VERSION ""

NS_ :

BS_:
BU_:
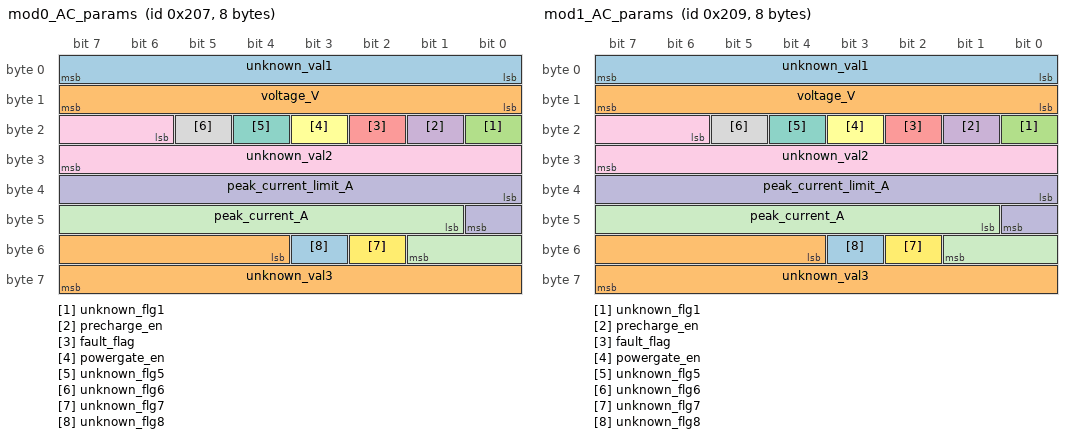
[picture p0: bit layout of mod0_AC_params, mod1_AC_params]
BO_ 519 mod0_AC_params: 8 Vector__XXX
   SG_ unknown_val1 : 0|8@1+ (1,0) [0|1] "" Vector__XXX
   SG_ voltage_V : 8|8@1+ (1,0) [0|1] "" Vector__XXX
   SG_ unknown_flg1 : 16|1@1+ (1,0) [0|1] "" Vector__XXX
   SG_ precharge_en : 17|1@1+ (1,0) [0|1] "" Vector__XXX
   SG_ fault_flag : 18|1@1+ (1,0) [0|1] "" Vector__XXX
   SG_ powergate_en : 19|1@1+ (1,0) [0|1] "" Vector__XXX
   SG_ unknown_flg5 : 20|1@1+ (1,0) [0|1] "" Vector__XXX
   SG_ unknown_flg6 : 21|1@1+ (1,0) [0|1] "" Vector__XXX
   SG_ unknown_val2 : 22|10@1- (1,0) [0|1] "" Vector__XXX
   SG_ peak_current_limit_A : 32|9@1+ (0.1,0) [0|1] "" Vector__XXX
   SG_ peak_current_A : 41|9@1+ (0.1,0) [0|1] "" Vector__XXX
   SG_ unknown_flg7 : 50|1@1+ (1,0) [0|1] "" Vector__XXX
   SG_ unknown_flg8 : 51|1@1+ (1,0) [0|1] "" Vector__XXX
   SG_ unknown_val3 : 52|12@1+ (1,0) [0|1] "" Vector__XXX

BO_ 521 mod1_AC_params: 8 Vector__XXX
   SG_ unknown_val1 : 0|8@1+ (1,0) [0|1] "" Vector__XXX
   SG_ voltage_V : 8|8@1+ (1,0) [0|1] "" Vector__XXX
   SG_ unknown_flg1 : 16|1@1+ (1,0) [0|1] "" Vector__XXX
   SG_ precharge_en : 17|1@1+ (1,0) [0|1] "" Vector__XXX
   SG_ fault_flag : 18|1@1+ (1,0) [0|1] "" Vector__XXX
   SG_ powergate_en : 19|1@1+ (1,0) [0|1] "" Vector__XXX
   SG_ unknown_flg5 : 20|1@1+ (1,0) [0|1] "" Vector__XXX
   SG_ unknown_flg6 : 21|1@1+ (1,0) [0|1] "" Vector__XXX
   SG_ unknown_val2 : 22|10@1- (1,0) [0|1] "" Vector__XXX
   SG_ peak_current_limit_A : 32|9@1+ (0.1,0) [0|1] "" Vector__XXX
   SG_ peak_current_A : 41|9@1+ (0.1,0) [0|1] "" Vector__XXX
   SG_ unknown_flg7 : 50|1@1+ (1,0) [0|1] "" Vector__XXX
   SG_ unknown_flg8 : 51|1@1+ (1,0) [0|1] "" Vector__XXX
   SG_ unknown_val3 : 52|12@1+ (1,0) [0|1] "" Vector__XXX

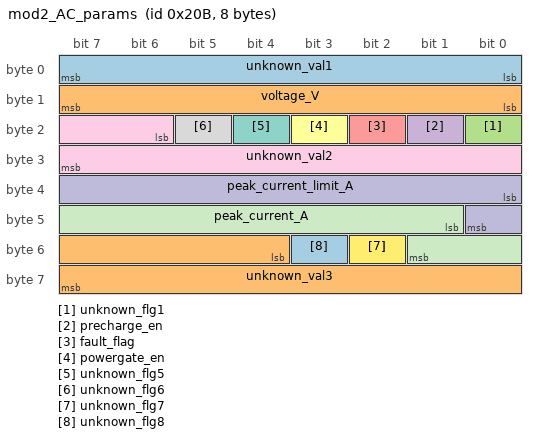
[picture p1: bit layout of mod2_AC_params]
BO_ 523 mod2_AC_params: 8 Vector__XXX
   SG_ unknown_val1 : 0|8@1+ (1,0) [0|1] "" Vector__XXX
   SG_ voltage_V : 8|8@1+ (1,0) [0|1] "" Vector__XXX
   SG_ unknown_flg1 : 16|1@1+ (1,0) [0|1] "" Vector__XXX
   SG_ precharge_en : 17|1@1+ (1,0) [0|1] "" Vector__XXX
   SG_ fault_flag : 18|1@1+ (1,0) [0|1] "" Vector__XXX
   SG_ powergate_en : 19|1@1+ (1,0) [0|1] "" Vector__XXX
   SG_ unknown_flg5 : 20|1@1+ (1,0) [0|1] "" Vector__XXX
   SG_ unknown_flg6 : 21|1@1+ (1,0) [0|1] "" Vector__XXX
   SG_ unknown_val2 : 22|10@1- (1,0) [0|1] "" Vector__XXX
   SG_ peak_current_limit_A : 32|9@1+ (0.1,0) [0|1] "" Vector__XXX
   SG_ peak_current_A : 41|9@1+ (0.1,0) [0|1] "" Vector__XXX
   SG_ unknown_flg7 : 50|1@1+ (1,0) [0|1] "" Vector__XXX
   SG_ unknown_flg8 : 51|1@1+ (1,0) [0|1] "" Vector__XXX
   SG_ unknown_val3 : 52|12@1+ (1,0) [0|1] "" Vector__XXX

CM_ SG_ 519 unknown_val2 "period_14.5sec._Peaks_affect_AC_voltage_V_a_little";
BA_DEF_ BO_ "GenMsgBackgroundColor" STRING ;
BA_DEF_ BO_ "GenMsgForegroundColor" STRING ;
BA_DEF_ BO_ "filterlabeling" INT 0 0;
BA_DEF_ BO_ "filterlabeling" INT 0 0;
BA_DEF_ BO_ "filterlabeling" INT 0 0;
BA_DEF_ BO_ "filterlabeling" INT 0 0;
BA_DEF_ BO_ "filterlabeling" INT 0 0;
BA_DEF_DEF_ "GenMsgBackgroundColor" "#ffffff";
BA_DEF_DEF_ "GenMsgForegroundColor" "#000000";
BA_DEF_DEF_ "filterlabeling" 1;
BA_DEF_DEF_ "filterlabeling" 1;
